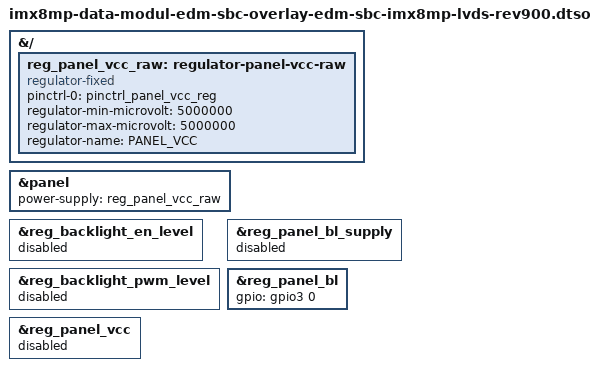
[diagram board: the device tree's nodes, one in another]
// SPDX-License-Identifier: (GPL-2.0+ OR MIT)
/*
 * Copyright 2023-2026 Marek Vasut
 */
/dts-v1/;
/plugin/;

&{/} {
	reg_panel_vcc_raw: regulator-panel-vcc-raw {
		compatible = "regulator-fixed";
		pinctrl-names = "default";
		pinctrl-0 = <&pinctrl_panel_vcc_reg>;
		regulator-min-microvolt = <5000000>;
		regulator-max-microvolt = <5000000>;
		regulator-name = "PANEL_VCC";
	};
};

&panel {
	power-supply = <&reg_panel_vcc_raw>;
};

&reg_backlight_en_level {
	status = "disabled";
};

&reg_backlight_pwm_level {
	status = "disabled";
};

&reg_panel_bl_supply {
	status = "disabled";
};

&reg_panel_bl {
	gpio = <&gpio3 0 0>;
};

&reg_panel_vcc {
	status = "disabled";
};
